# RockChip_RK3588 register map
Vendor: RockChip Electronics Co., Ltd.; Series: RK3588; File version: 0.1
Registers are 32-bit, read-write, no defined reset value unless marked. A register's access mark holds for its fields unless they carry their own. Offsets are from the block's base; [hi:lo] are bit positions.

## GRF_CSIDPHY0
Base 0xFD5B4000
Same registers: GRF_CSIDPHY1 0xFD5B5000
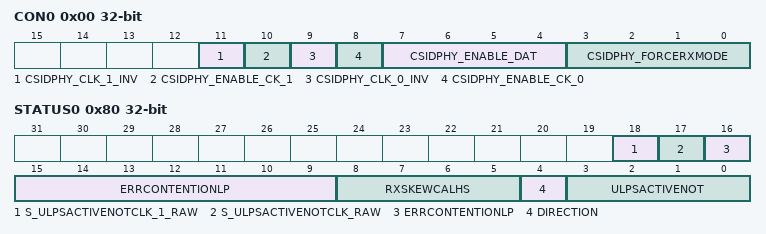
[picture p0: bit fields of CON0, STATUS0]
0x00 CON0 — CSIDPHY Control Register
  [11] CSIDPHY_CLK_1_INV — Invert CSIDPHY clock lane1 rxbyte clock
    1=INVERT (Invert CSIDPHY clock lane 1 rxbyte_clk_hs); 0=NORMAL (Do not invert CSIDPHY clock lane 1 rxbyte_clk_hs)
  [10] CSIDPHY_ENABLE_CK_1 — CSIDPHY Clock Lane 1 enable signal
    1=ACTIVE; 0=INACTIVE
  [9] CSIDPHY_CLK_0_INV — Invert CSIDPHY rxbyte clock
    1=INVERT (Invert CSIDPHY rxbyte_clk_hs); 0=NORMAL (Do not invert CSIDPHY rxbyte_clk_hs)
  [8] CSIDPHY_ENABLE_CK_0 — CSIDPHY Clock Lane enable signal
    1=ACTIVE; 0=INACTIVE
  [7:4] CSIDPHY_ENABLE_DAT — CSIDPHY enable lane module This active high signal forces the Lane Module out of "shutdown". All line drivers, receivers, terminators, and connection detectors are turned off when Enable is low. Enable is a level sensitive signal and does not depend on any clock.
  [3:0] CSIDPHY_FORCERXMODE — CSIDPHY force receive mode Force Lane Module Into Receive mode / Wait for Stop state.This signal allows the protocol to initialize a Lane Module, or force a bi-directional Lane Module, into receive mode.
0x80 STATUS0 ro — CSIDPHY Status Register
  [18] S_ULPSACTIVENOTCLK_1_RAW — ULP State (not) Active 1 status This active low signal is asserted to indicate that the Lane is in ULP state.
  [17] S_ULPSACTIVENOTCLK_RAW — ULP State (not) Active status This active low signal is asserted to indicate that the Lane is in ULP state.
  [16:9] ERRCONTENTIONLP — LP Contention Error This active high signal is asserted when the Lane Module detects a contention situation on a line while trying to drive the line low.
  [8:5] RXSKEWCALHS — High-Speed Receive Skew Calibration This optional active high signal indicates that the high speed deskew burst is being received. RxSkewCalHS is set to the active state when the all-ones sync pattern is received, and is cleared to the inactive state when Dp and Dn transition back to the LP-11 Stop State.
  [4] DIRECTION — This signal is used to indicate the current direction of the Lane interconnects. When pin_direction =0, the Lane is in transmit mode. When pin_direction =1, the Lane is in receive mode.
  [3:0] ULPSACTIVENOT — ULP State (not) Active. This active low signal is asserted to indicate that the Lane is in ULP state.

## GRF_GPU
Base 0xFD5A0000
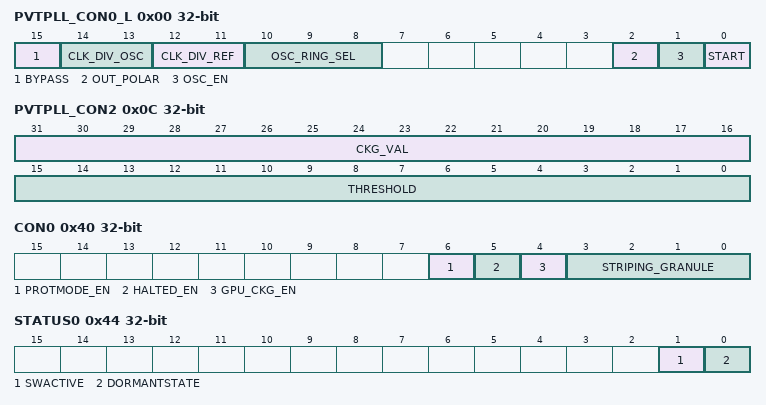
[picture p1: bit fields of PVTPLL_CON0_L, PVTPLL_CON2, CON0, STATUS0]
0x00 PVTPLL_CON0_L — PVTPLL Control Register 0
  [15] BYPASS
    0=SUPPORT (Support glitch-free frequency conversion.); 1=NOT_SUPPORT
  [14:13] CLK_DIV_OSC — Frequency division factor for osc_clk.
  [12:11] CLK_DIV_REF — Frequency division factor for ref_clk.
  [10:8] OSC_RING_SEL — Oscillator ring channel select.
  [2] OUT_POLAR
    0=OUT_1 (Out=1 when need to increase voltage.); 1=OUT_0 (Out=0 when need to increase voltage.)
  [1] OSC_EN — Oscillator ring enable.
    1=ENABLE; 0=DISABLE
  [0] START
    1=START (PVTPLL monitor start.)
0x04 PVTPLL_CON0_H — PVTPLL Control Register 0
  [5:0] RING_LENGTH_SEL — Oscillator ring inverter length select.
0x08 PVTPLL_CON1 — PVTPLL Control Register 1
  [31:0] CAL_CNT — Target frequency value.
0x0C PVTPLL_CON2 — PVTPLL Control Register 2
  [31:16] CKG_VAL — Clock gating interval control count value.
  [15:0] THRESHOLD — Count difference threshold value.
0x10 PVTPLL_CON3 — PVTPLL Control Register 3
  [31:0] REF_CNT — Frequency measurement period setting value.
0x24 MEMCFG_CON0 — Memory Configuration Control Register 0
  [31:0] MEMCFG_HDSPRF — memory configuration of hdsprf type bit 0: TEST1 bit 1: TEST_RNM bit 4~2: RM bit 5: WMD bit 7: LS bit 11~10: WPULSE bit 13~12: RA
0x28 MEMCFG_CON1 — Memory Configuration Control Register 1
  [31:0] MEMCFG_UHDPDPRF — memory configuration of uhdpdprf type. bit 0: TEST1 bit 1: TEST_RNM bit 4~2: RM bit 5: WMDA bit 7: LS
0x40 CON0 — GPU Control Register 0
  [6] PROTMODE_EN — gpu protected mode enable.
  [5] HALTED_EN — daplite2m halted enable.
  [4] GPU_CKG_EN — Clock gate enable.
  [3:0] STRIPING_GRANULE — Memory striping control. This signal must be set during the GPU reset and remain static during operation.
0x44 STATUS0 — GPU Status Register 0
  [1] SWACTIVE ro — Serial wire active. high when the debug port is operating using the serial wire protocol.
    1=ACTIVE; 0=INACTIVE
  [0] DORMANTSTATE ro — Active-high status to indicate that none of the protocol engines are selected and that the DP is in dormant state.
    1=DORMANT; 0=NOT_DORMANT
